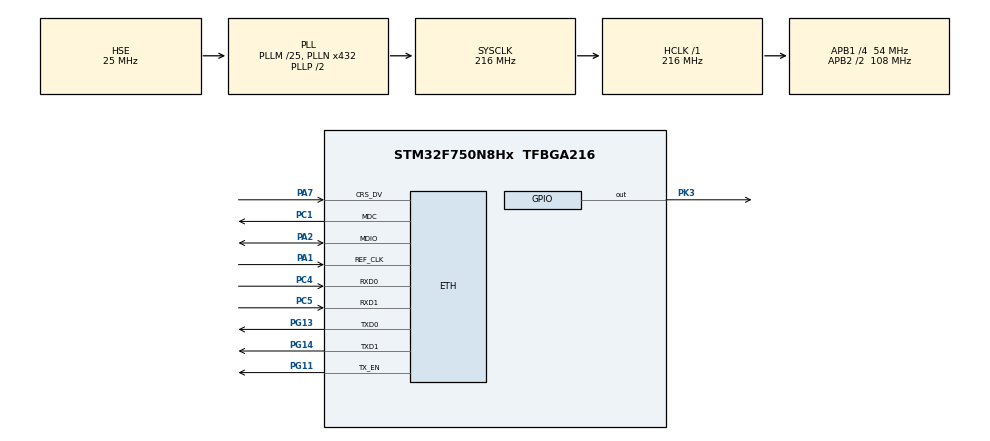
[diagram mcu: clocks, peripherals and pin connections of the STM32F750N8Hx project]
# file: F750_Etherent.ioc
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CORTEX_M7.AccessPermission-Cortex_Memory_Protection_Unit_Region1_Settings=MPU_REGION_FULL_ACCESS
CORTEX_M7.AccessPermission-Cortex_Memory_Protection_Unit_Region2_Settings=MPU_REGION_FULL_ACCESS
CORTEX_M7.AccessPermission-Cortex_Memory_Protection_Unit_Region4_Settings=MPU_REGION_FULL_ACCESS
CORTEX_M7.BaseAddress-Cortex_Memory_Protection_Unit_Region0_Settings=0x90000000
CORTEX_M7.BaseAddress-Cortex_Memory_Protection_Unit_Region1_Settings=0x90000000
CORTEX_M7.BaseAddress-Cortex_Memory_Protection_Unit_Region2_Settings=0x90000000
CORTEX_M7.BaseAddress-Cortex_Memory_Protection_Unit_Region4_Settings=0x2004c000
CORTEX_M7.CPU_DCache=Enabled
CORTEX_M7.CPU_ICache=Enabled
CORTEX_M7.DisableExec-Cortex_Memory_Protection_Unit_Region0_Settings=MPU_INSTRUCTION_ACCESS_DISABLE
CORTEX_M7.DisableExec-Cortex_Memory_Protection_Unit_Region1_Settings=MPU_INSTRUCTION_ACCESS_DISABLE
CORTEX_M7.DisableExec-Cortex_Memory_Protection_Unit_Region4_Settings=MPU_INSTRUCTION_ACCESS_DISABLE
CORTEX_M7.Enable-Cortex_Memory_Protection_Unit_Region0_Settings=MPU_REGION_ENABLE
CORTEX_M7.Enable-Cortex_Memory_Protection_Unit_Region1_Settings=MPU_REGION_ENABLE
CORTEX_M7.Enable-Cortex_Memory_Protection_Unit_Region2_Settings=MPU_REGION_ENABLE
CORTEX_M7.Enable-Cortex_Memory_Protection_Unit_Region4_Settings=MPU_REGION_ENABLE
CORTEX_M7.IsBufferable-Cortex_Memory_Protection_Unit_Region1_Settings=MPU_ACCESS_BUFFERABLE
CORTEX_M7.IsBufferable-Cortex_Memory_Protection_Unit_Region2_Settings=MPU_ACCESS_BUFFERABLE
CORTEX_M7.IsCacheable-Cortex_Memory_Protection_Unit_Region1_Settings=MPU_ACCESS_CACHEABLE
CORTEX_M7.IsCacheable-Cortex_Memory_Protection_Unit_Region2_Settings=MPU_ACCESS_CACHEABLE
CORTEX_M7.IsShareable-Cortex_Memory_Protection_Unit_Region4_Settings=MPU_ACCESS_NOT_SHAREABLE
CORTEX_M7.MPU_Control=MPU_PRIVILEGED_DEFAULT
CORTEX_M7.PREFETCH_ENABLE=1
CORTEX_M7.Size-Cortex_Memory_Protection_Unit_Region0_Settings=MPU_REGION_SIZE_512MB
CORTEX_M7.Size-Cortex_Memory_Protection_Unit_Region1_Settings=MPU_REGION_SIZE_16MB
CORTEX_M7.Size-Cortex_Memory_Protection_Unit_Region2_Settings=MPU_REGION_SIZE_1MB
CORTEX_M7.Size-Cortex_Memory_Protection_Unit_Region4_Settings=MPU_REGION_SIZE_32KB
CORTEX_M7.TypeExtField-Cortex_Memory_Protection_Unit_Region4_Settings=MPU_TEX_LEVEL1
ETH.MediaInterface=HAL_ETH_RMII_MODE
ETH.RxMode=ETH_RXPOLLING_MODE
LWIP.BSP.number=1
LWIP.GATEWAY_ADDRESS=192.168.000.001
LWIP.IP_ADDRESS=192.168.000.123
LWIP.LWIP_DHCP=0
LWIP.LWIP_RAM_HEAP_POINTER=0x20048000
LWIP.MEM_SIZE=2*1024
LWIP.NETMASK_ADDRESS=255.255.255.000
LWIP.Version=v2.1.2_Cube
LWIP0.BSP.STBoard=false
LWIP0.BSP.api=BSP_COMPONENT_DRIVER
LWIP0.BSP.component=LAN8742
LWIP0.BSP.instance=LAN8742
LWIP0.BSP.name=Driver_PHY
LWIP0.BSP.semaphore=S_LAN8742
LWIP0.BSP.solution=LAN8742
Mcu.Family=STM32F7
Mcu.Name=STM32F750N8Hx
Mcu.Package=TFBGA216
NVIC.PriorityGroup=NVIC_PRIORITYGROUP_4
PA1.Mode=RMII
PA1.Signal=ETH_REF_CLK
PA2.Mode=RMII
PA2.Signal=ETH_MDIO
PA7.Mode=RMII
PA7.Signal=ETH_CRS_DV
PC1.Mode=RMII
PC1.Signal=ETH_MDC
PC4.Mode=RMII
PC4.Signal=ETH_RXD0
PC5.Mode=RMII
PC5.Signal=ETH_RXD1
PG11.Mode=RMII
PG11.Signal=ETH_TX_EN
PG13.Mode=RMII
PG13.Signal=ETH_TXD0
PG14.Mode=RMII
PG14.Signal=ETH_TXD1
PH0/OSC_IN.Mode=HSE-External-Oscillator
PH0/OSC_IN.Signal=RCC_OSC_IN
PH1/OSC_OUT.Mode=HSE-External-Oscillator
PH1/OSC_OUT.Signal=RCC_OSC_OUT
PK3.Signal=GPIO_Output
ProjectManager.HeapSize=0x200
ProjectManager.StackSize=0x400
ProjectManager.TargetToolchain=STM32CubeIDE
RCC.AHBFreq_Value=216000000
RCC.APB1CLKDivider=RCC_HCLK_DIV4
RCC.APB1Freq_Value=54000000
RCC.APB1TimFreq_Value=108000000
RCC.APB2CLKDivider=RCC_HCLK_DIV2
RCC.APB2Freq_Value=108000000
RCC.APB2TimFreq_Value=216000000
RCC.CortexFreq_Value=216000000
RCC.FLatency=FLASH_LATENCY_7
RCC.HCLKFreq_Value=216000000
RCC.HSE_VALUE=25000000
RCC.HSI_VALUE=16000000
RCC.LSE_VALUE=32768
RCC.PLLM=25
RCC.PLLN=432
RCC.PLLSourceVirtual=RCC_PLLSOURCE_HSE
RCC.PWR_Regulator_Voltage_Scale=PWR_REGULATOR_VOLTAGE_SCALE1
RCC.SYSCLKFreq_VALUE=216000000
RCC.SYSCLKSource=RCC_SYSCLKSOURCE_PLLCLK
RCC.USBFreq_Value=216000000
RCC.VCOOutputFreq_Value=432000000
VP_LWIP_VS_Enabled.Mode=Enabled
board=STM32F7508-DK

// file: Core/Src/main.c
/* USER CODE BEGIN Header */
/**
  ******************************************************************************
  * @file           : main.c
  * @brief          : Main program body
  ******************************************************************************
  * @attention
  *
  * Copyright (c) 2025 STMicroelectronics.
  * All rights reserved.
  *
  * This software is licensed under terms that can be found in the LICENSE file
  * in the root directory of this software component.
  * If no LICENSE file comes with this software, it is provided AS-IS.
  *
  ******************************************************************************
  */
/* USER CODE END Header */
#include "main.h"
#include "lwip.h"

void SystemClock_Config(void);
static void MPU_Config(void);
static void MX_GPIO_Init(void);

/* USER CODE BEGIN 0 */
extern struct netif gnetif;
/* USER CODE END 0 */

int main(void)
{

  /* USER CODE BEGIN 1 */
	int wait = 100000;
	while (wait-- > 0);

  /* USER CODE END 1 */

  /* MPU Configuration--------------------------------------------------------*/
  MPU_Config();

  /* Enable the CPU Cache */

  /* Enable I-Cache---------------------------------------------------------*/
  SCB_EnableICache();

  /* Enable D-Cache---------------------------------------------------------*/
  SCB_EnableDCache();

  /* MCU Configuration--------------------------------------------------------*/

  /* Reset of all peripherals, Initializes the Flash interface and the Systick. */
  HAL_Init();

  /* USER CODE BEGIN Init */

  HAL_Delay (1000);

  /* USER CODE END Init */

  /* Configure the system clock */
  SystemClock_Config();

  /* Initialize all configured peripherals */
  MX_GPIO_Init();
  MX_LWIP_Init();

  /* Infinite loop */
  while (1)
  {

    /* USER CODE BEGIN 3 */

	  ethernetif_input(&gnetif);

	  sys_check_timeouts();

//	  HAL_GPIO_TogglePin (GPIOK, GPIO_PIN_3);
//	  HAL_Delay (1000);
  }
  /* USER CODE END 3 */
}

void SystemClock_Config(void)
{
  RCC_OscInitTypeDef RCC_OscInitStruct = {0};
  RCC_ClkInitTypeDef RCC_ClkInitStruct = {0};

  /** Configure the main internal regulator output voltage
  */
  __HAL_RCC_PWR_CLK_ENABLE();
  __HAL_PWR_VOLTAGESCALING_CONFIG(PWR_REGULATOR_VOLTAGE_SCALE1);

  /** Initializes the RCC Oscillators according to the specified parameters
  * in the RCC_OscInitTypeDef structure.
  */
  RCC_OscInitStruct.OscillatorType = RCC_OSCILLATORTYPE_HSE;
  RCC_OscInitStruct.HSEState = RCC_HSE_ON;
  RCC_OscInitStruct.PLL.PLLState = RCC_PLL_ON;
  RCC_OscInitStruct.PLL.PLLSource = RCC_PLLSOURCE_HSE;
  RCC_OscInitStruct.PLL.PLLM = 25;
  RCC_OscInitStruct.PLL.PLLN = 432;
  RCC_OscInitStruct.PLL.PLLP = RCC_PLLP_DIV2;
  RCC_OscInitStruct.PLL.PLLQ = 2;
  if (HAL_RCC_OscConfig(&RCC_OscInitStruct) != HAL_OK)
  {
    Error_Handler();
  }

  /** Activate the Over-Drive mode
  */
  if (HAL_PWREx_EnableOverDrive() != HAL_OK)
  {
    Error_Handler();
  }

  /** Initializes the CPU, AHB and APB buses clocks
  */
  RCC_ClkInitStruct.ClockType = RCC_CLOCKTYPE_HCLK|RCC_CLOCKTYPE_SYSCLK
                              |RCC_CLOCKTYPE_PCLK1|RCC_CLOCKTYPE_PCLK2;
  RCC_ClkInitStruct.SYSCLKSource = RCC_SYSCLKSOURCE_PLLCLK;
  RCC_ClkInitStruct.AHBCLKDivider = RCC_SYSCLK_DIV1;
  RCC_ClkInitStruct.APB1CLKDivider = RCC_HCLK_DIV4;
  RCC_ClkInitStruct.APB2CLKDivider = RCC_HCLK_DIV2;

  if (HAL_RCC_ClockConfig(&RCC_ClkInitStruct, FLASH_LATENCY_7) != HAL_OK)
  {
    Error_Handler();
  }
}

static void MX_GPIO_Init(void)
{
  GPIO_InitTypeDef GPIO_InitStruct = {0};

  /* GPIO Ports Clock Enable */
  __HAL_RCC_GPIOG_CLK_ENABLE();
  __HAL_RCC_GPIOK_CLK_ENABLE();
  __HAL_RCC_GPIOH_CLK_ENABLE();
  __HAL_RCC_GPIOC_CLK_ENABLE();
  __HAL_RCC_GPIOA_CLK_ENABLE();

  /*Configure GPIO pin Output Level */
  HAL_GPIO_WritePin(GPIOK, GPIO_PIN_3, GPIO_PIN_RESET);

  /*Configure GPIO pin : PK3 */
  GPIO_InitStruct.Pin = GPIO_PIN_3;
  GPIO_InitStruct.Mode = GPIO_MODE_OUTPUT_PP;
  GPIO_InitStruct.Pull = GPIO_NOPULL;
  GPIO_InitStruct.Speed = GPIO_SPEED_FREQ_LOW;
  HAL_GPIO_Init(GPIOK, &GPIO_InitStruct);

}

 /* MPU Configuration */

void MPU_Config(void)
{
  MPU_Region_InitTypeDef MPU_InitStruct = {0};

  /* Disables the MPU */
  HAL_MPU_Disable();

  /** Initializes and configures the Region and the memory to be protected
  */
  MPU_InitStruct.Enable = MPU_REGION_ENABLE;
  MPU_InitStruct.Number = MPU_REGION_NUMBER0;
  MPU_InitStruct.BaseAddress = 0x90000000;
  MPU_InitStruct.Size = MPU_REGION_SIZE_512MB;
  MPU_InitStruct.SubRegionDisable = 0x0;
  MPU_InitStruct.TypeExtField = MPU_TEX_LEVEL0;
  MPU_InitStruct.AccessPermission = MPU_REGION_NO_ACCESS;
  MPU_InitStruct.DisableExec = MPU_INSTRUCTION_ACCESS_DISABLE;
  MPU_InitStruct.IsShareable = MPU_ACCESS_NOT_SHAREABLE;
  MPU_InitStruct.IsCacheable = MPU_ACCESS_NOT_CACHEABLE;
  MPU_InitStruct.IsBufferable = MPU_ACCESS_NOT_BUFFERABLE;

  HAL_MPU_ConfigRegion(&MPU_InitStruct);

  /** Initializes and configures the Region and the memory to be protected
  */
  MPU_InitStruct.Number = MPU_REGION_NUMBER1;
  MPU_InitStruct.Size = MPU_REGION_SIZE_16MB;
  MPU_InitStruct.AccessPermission = MPU_REGION_FULL_ACCESS;
  MPU_InitStruct.IsCacheable = MPU_ACCESS_CACHEABLE;
  MPU_InitStruct.IsBufferable = MPU_ACCESS_BUFFERABLE;

  HAL_MPU_ConfigRegion(&MPU_InitStruct);

  /** Initializes and configures the Region and the memory to be protected
  */
  MPU_InitStruct.Number = MPU_REGION_NUMBER2;
  MPU_InitStruct.Size = MPU_REGION_SIZE_1MB;
  MPU_InitStruct.DisableExec = MPU_INSTRUCTION_ACCESS_ENABLE;

  HAL_MPU_ConfigRegion(&MPU_InitStruct);

  /** Initializes and configures the Region and the memory to be protected
  */
  MPU_InitStruct.Number = MPU_REGION_NUMBER4;
  MPU_InitStruct.BaseAddress = 0x2004c000;
  MPU_InitStruct.Size = MPU_REGION_SIZE_32KB;
  MPU_InitStruct.TypeExtField = MPU_TEX_LEVEL1;
  MPU_InitStruct.DisableExec = MPU_INSTRUCTION_ACCESS_DISABLE;
  MPU_InitStruct.IsCacheable = MPU_ACCESS_NOT_CACHEABLE;
  MPU_InitStruct.IsBufferable = MPU_ACCESS_NOT_BUFFERABLE;

  HAL_MPU_ConfigRegion(&MPU_InitStruct);
  /* Enables the MPU */
  HAL_MPU_Enable(MPU_PRIVILEGED_DEFAULT);

}

void Error_Handler(void)
{
  __disable_irq();
  while (1)
  {
  }
}
